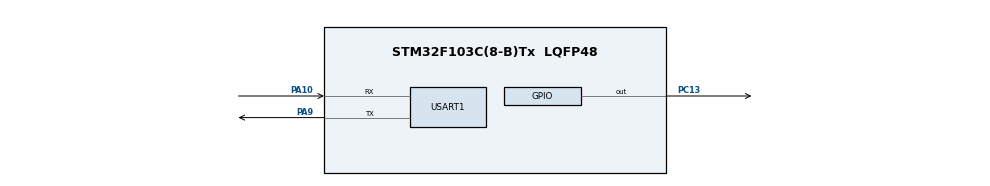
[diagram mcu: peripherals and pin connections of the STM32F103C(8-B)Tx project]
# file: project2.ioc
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Dma.Request0=USART1_RX
Dma.Request1=USART1_TX
Dma.USART1_RX.0.Direction=DMA_PERIPH_TO_MEMORY
Dma.USART1_RX.0.Instance=DMA1_Channel5
Dma.USART1_RX.0.MemDataAlignment=DMA_MDATAALIGN_BYTE
Dma.USART1_RX.0.MemInc=DMA_MINC_ENABLE
Dma.USART1_RX.0.Mode=DMA_NORMAL
Dma.USART1_RX.0.PeriphDataAlignment=DMA_PDATAALIGN_BYTE
Dma.USART1_RX.0.PeriphInc=DMA_PINC_DISABLE
Dma.USART1_RX.0.Priority=DMA_PRIORITY_MEDIUM
Dma.USART1_TX.1.Direction=DMA_MEMORY_TO_PERIPH
Dma.USART1_TX.1.Instance=DMA1_Channel4
Dma.USART1_TX.1.MemDataAlignment=DMA_MDATAALIGN_BYTE
Dma.USART1_TX.1.MemInc=DMA_MINC_ENABLE
Dma.USART1_TX.1.Mode=DMA_NORMAL
Dma.USART1_TX.1.PeriphDataAlignment=DMA_PDATAALIGN_BYTE
Dma.USART1_TX.1.PeriphInc=DMA_PINC_DISABLE
Dma.USART1_TX.1.Priority=DMA_PRIORITY_MEDIUM
Mcu.Family=STM32F1
Mcu.Name=STM32F103C(8-B)Tx
Mcu.Package=LQFP48
NVIC.DMA1_Channel4_IRQn=true\:0\:0\:false\:false\:true\:false\:true\:true
NVIC.DMA1_Channel5_IRQn=true\:0\:0\:false\:false\:true\:false\:true\:true
NVIC.PriorityGroup=NVIC_PRIORITYGROUP_4
NVIC.USART1_IRQn=true\:0\:0\:false\:false\:true\:true\:true\:true
PA10.Mode=Asynchronous
PA10.Signal=USART1_RX
PA13.Mode=Serial_Wire
PA13.Signal=SYS_JTMS-SWDIO
PA14.Mode=Serial_Wire
PA14.Signal=SYS_JTCK-SWCLK
PA9.Mode=Asynchronous
PA9.Signal=USART1_TX
PC13-TAMPER-RTC.GPIO_ModeDefaultOutputPP=GPIO_MODE_OUTPUT_OD
PC13-TAMPER-RTC.GPIO_PuPd=GPIO_NOPULL
PC13-TAMPER-RTC.PinState=GPIO_PIN_SET
PC13-TAMPER-RTC.Signal=GPIO_Output
ProjectManager.HeapSize=0x200
ProjectManager.StackSize=0x400
ProjectManager.TargetToolchain=MDK-ARM V5.32
RCC.APB1Freq_Value=8000000
RCC.APB2Freq_Value=8000000
USART1.VirtualMode=VM_ASYNC
board=custom

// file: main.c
/* USER CODE BEGIN Header */
/**
  ******************************************************************************
  * @file           : main.c
  * @brief          : Main program body
  ******************************************************************************
  * @attention
  *
  * Copyright (c) 2025 STMicroelectronics.
  * All rights reserved.
  *
  * This software is licensed under terms that can be found in the LICENSE file
  * in the root directory of this software component.
  * If no LICENSE file comes with this software, it is provided AS-IS.
  *
  ******************************************************************************
  */
/* USER CODE END Header */
#include "main.h"
#include "dma.h"
#include "usart.h"
#include "gpio.h"
#include <math.h>
#include "bsp_usart.h"

/* USER CODE BEGIN PV */
#define PI 3.1415926
uint8_t Rx_Buffer[10];
uint8_t  s=0;
uint8_t *a=&s;
void Serialplot_Call_Back(uint8_t *buffer,uint16_t length){
	a=&buffer[0];
}
/* USER CODE END PV */

void SystemClock_Config(void);

int main(void)
{

  /* MCU Configuration--------------------------------------------------------*/

  /* Reset of all peripherals, Initializes the Flash interface and the Systick. */
  HAL_Init();

  /* Configure the system clock */
  SystemClock_Config();

  /* Initialize all configured peripherals */
  MX_GPIO_Init();
  MX_DMA_Init();
  MX_USART1_UART_Init();

  /* Infinite loop */
  /* USER CODE BEGIN WHILE */
 Uart_Init(&huart1, Rx_Buffer, 10,Serialplot_Call_Back);
uint8_t Tx_Buffer[129];
Tx_Buffer[0]=0xAB;
if(*a==1){HAL_UART_Transmit(&huart1,&s,2,HAL_MAX_DELAY);}
  while (1)
  {
		if(*a==1){HAL_GPIO_WritePin(GPIOC,GPIO_PIN_13,GPIO_PIN_RESET);}
		else if(*a==0){HAL_GPIO_WritePin(GPIOC,GPIO_PIN_13,GPIO_PIN_SET);}
    /* USER CODE END WHILE */

    /* USER CODE BEGIN 3 */
		for(int i=1;i<=31;i+=2){
			float data=0;
			unsigned char* p=NULL;
			data=(sin((float)((i-1)/2)*22.5*PI/180));
			p=(unsigned char*)(&data);
			int j=(i-1)*4+1;
			for (int k=0;k<4;k++){
				Tx_Buffer[j+k]=*(p+k);
			}
		}
		for(int i=2;i<=32;i+=2){
			float data=0;
			unsigned char* p=NULL;
			data=(cos((float)((i-1)/2)*22.5*PI/180));
			p=(unsigned char*)(&data);
			int j=(i-1)*4+1;
			for (int k=0;k<4;k++){
				Tx_Buffer[j+k]=*(p+k);
			}
		}
UART_Send_Data(&huart1,Tx_Buffer,129);
		HAL_Delay(100);
  }
  /* USER CODE END 3 */
}

void SystemClock_Config(void)
{
  RCC_OscInitTypeDef RCC_OscInitStruct = {0};
  RCC_ClkInitTypeDef RCC_ClkInitStruct = {0};

  /** Initializes the RCC Oscillators according to the specified parameters
  * in the RCC_OscInitTypeDef structure.
  */
  RCC_OscInitStruct.OscillatorType = RCC_OSCILLATORTYPE_HSI;
  RCC_OscInitStruct.HSIState = RCC_HSI_ON;
  RCC_OscInitStruct.HSICalibrationValue = RCC_HSICALIBRATION_DEFAULT;
  RCC_OscInitStruct.PLL.PLLState = RCC_PLL_NONE;
  if (HAL_RCC_OscConfig(&RCC_OscInitStruct) != HAL_OK)
  {
    Error_Handler();
  }

  /** Initializes the CPU, AHB and APB buses clocks
  */
  RCC_ClkInitStruct.ClockType = RCC_CLOCKTYPE_HCLK|RCC_CLOCKTYPE_SYSCLK
                              |RCC_CLOCKTYPE_PCLK1|RCC_CLOCKTYPE_PCLK2;
  RCC_ClkInitStruct.SYSCLKSource = RCC_SYSCLKSOURCE_HSI;
  RCC_ClkInitStruct.AHBCLKDivider = RCC_SYSCLK_DIV1;
  RCC_ClkInitStruct.APB1CLKDivider = RCC_HCLK_DIV1;
  RCC_ClkInitStruct.APB2CLKDivider = RCC_HCLK_DIV1;

  if (HAL_RCC_ClockConfig(&RCC_ClkInitStruct, FLASH_LATENCY_0) != HAL_OK)
  {
    Error_Handler();
  }
}

void Error_Handler(void)
{
  __disable_irq();
  while (1)
  {
  }
}
